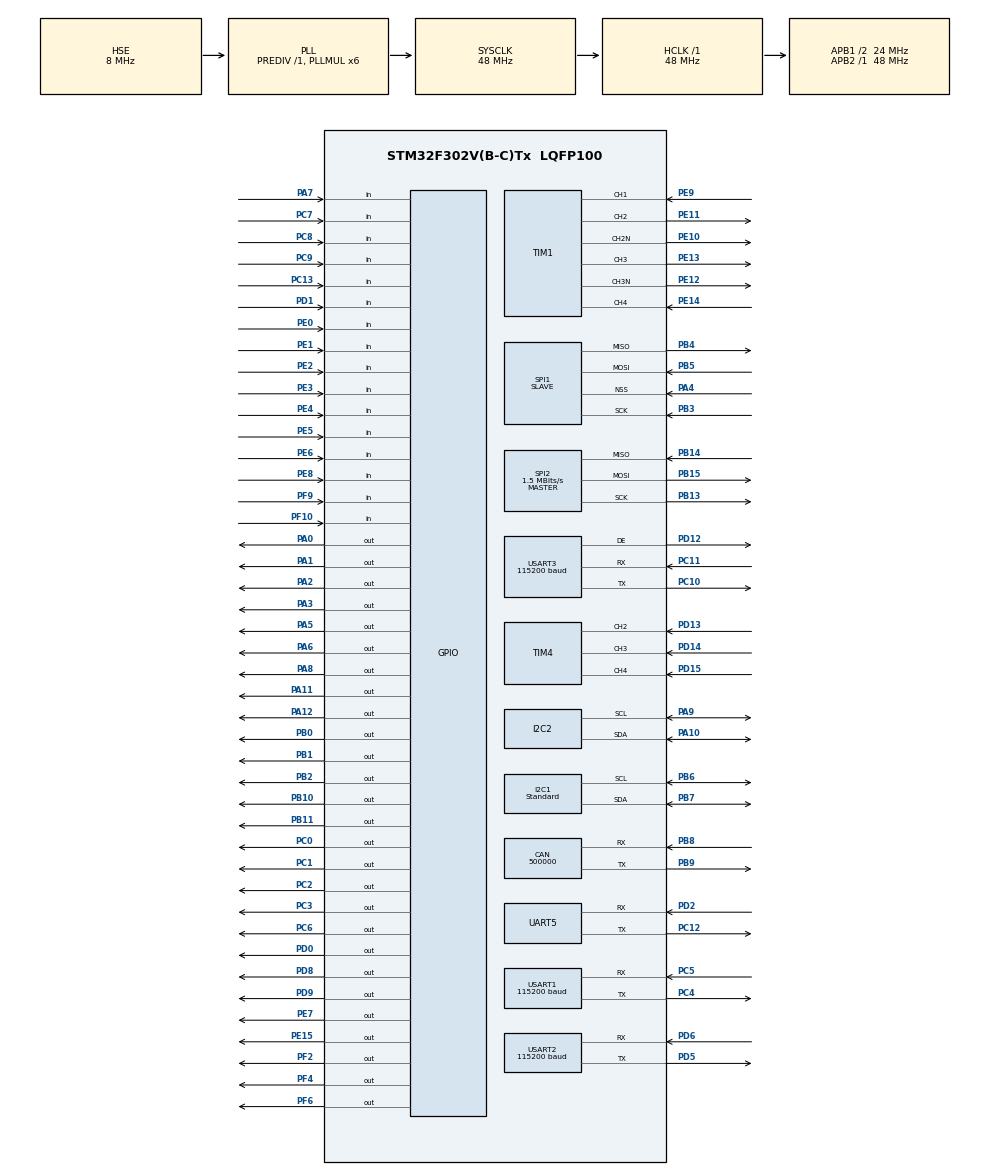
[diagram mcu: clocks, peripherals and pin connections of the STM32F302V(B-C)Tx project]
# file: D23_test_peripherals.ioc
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CAN.CalculateBaudRate=500000
CAN.CalculateTimeBit=2000
CAN.CalculateTimeQuantum=666.6666666666666
I2C1.AddressingMode=I2C_ADDRESSINGMODE_7BIT
I2C1.I2C_Speed_Mode=I2C_Standard
Mcu.Family=STM32F3
Mcu.Name=STM32F302V(B-C)Tx
Mcu.Package=LQFP100
NVIC.PriorityGroup=NVIC_PRIORITYGROUP_4
PA0.Signal=GPIO_Output
PA1.Signal=GPIO_Output
PA10.Mode=I2C
PA10.Signal=I2C2_SDA
PA11.Signal=GPIO_Output
PA12.Signal=GPIO_Output
PA13.Mode=Serial_Wire
PA13.Signal=SYS_JTMS-SWDIO
PA14.Mode=Serial_Wire
PA14.Signal=SYS_JTCK-SWCLK
PA15.Signal=SYS_JTDI
PA2.Signal=GPIO_Output
PA3.Signal=GPIO_Output
PA4.Mode=NSS_Signal_Hard_Input
PA4.Signal=SPI1_NSS
PA5.Signal=GPIO_Output
PA6.Signal=GPIO_Output
PA7.Signal=GPIO_Input
PA8.Signal=GPIO_Output
PA9.Mode=I2C
PA9.Signal=I2C2_SCL
PB0.Signal=GPIO_Output
PB1.Signal=GPIO_Output
PB10.Signal=GPIO_Output
PB11.Signal=GPIO_Output
PB12.Signal=SPI2_NSS
PB13.Mode=Full_Duplex_Master
PB13.Signal=SPI2_SCK
PB14.Mode=Full_Duplex_Master
PB14.Signal=SPI2_MISO
PB15.Mode=Full_Duplex_Master
PB15.Signal=SPI2_MOSI
PB2.Signal=GPIO_Output
PB3.Mode=Full_Duplex_Slave
PB3.Signal=SPI1_SCK
PB4.Mode=Full_Duplex_Slave
PB4.Signal=SPI1_MISO
PB5.Mode=Full_Duplex_Slave
PB5.Signal=SPI1_MOSI
PB6.Mode=I2C
PB6.Signal=I2C1_SCL
PB7.Mode=I2C
PB7.Signal=I2C1_SDA
PB8.Mode=CAN_Activate
PB8.Signal=CAN_RX
PB9.Mode=CAN_Activate
PB9.Signal=CAN_TX
PC0.Signal=GPIO_Output
PC1.Signal=GPIO_Output
PC10.Mode=Asynchronous
PC10.Signal=USART3_TX
PC11.Mode=Asynchronous
PC11.Signal=USART3_RX
PC12.Mode=Asynchronous
PC12.Signal=UART5_TX
PC13.Signal=GPIO_Input
PC14-OSC32_IN.Mode=LSE-External-Oscillator
PC14-OSC32_IN.Signal=RCC_OSC32_IN
PC15-OSC32_OUT.Mode=LSE-External-Oscillator
PC15-OSC32_OUT.Signal=RCC_OSC32_OUT
PC2.Signal=GPIO_Output
PC3.Signal=GPIO_Output
PC4.Mode=Asynchronous
PC4.Signal=USART1_TX
PC5.Mode=Asynchronous
PC5.Signal=USART1_RX
PC6.Signal=GPIO_Output
PC7.Signal=GPIO_Input
PC8.Signal=GPIO_Input
PC9.Signal=GPIO_Input
PD0.Signal=GPIO_Output
PD1.Signal=GPIO_Input
PD10.Signal=USART3_CK
PD11.Signal=USART3_CTS
PD12.Mode=Hardware Flow Control (RS485)
PD12.Signal=USART3_DE
PD13.Signal=S_TIM4_CH2
PD14.Signal=S_TIM4_CH3
PD15.Signal=S_TIM4_CH4
PD2.Mode=Asynchronous
PD2.Signal=UART5_RX
PD3.Signal=USART2_CTS
PD4.Signal=USART2_RTS
PD5.Mode=Asynchronous
PD5.Signal=USART2_TX
PD6.Mode=Asynchronous
PD6.Signal=USART2_RX
PD7.Signal=USART2_CK
PD8.Signal=GPIO_Output
PD9.Signal=GPIO_Output
PE0.Signal=GPIO_Input
PE1.Signal=GPIO_Input
PE10.Mode=Output Compare2 CH2 CH2N
PE10.Signal=TIM1_CH2N
PE11.Signal=S_TIM1_CH2
PE12.Mode=Output Compare3 CH3 CH3N
PE12.Signal=TIM1_CH3N
PE13.Signal=S_TIM1_CH3
PE14.Signal=S_TIM1_CH4
PE15.Signal=GPIO_Output
PE2.Signal=GPIO_Input
PE3.Signal=GPIO_Input
PE4.Signal=GPIO_Input
PE5.Signal=GPIO_Input
PE6.Signal=GPIO_Input
PE7.Signal=GPIO_Output
PE8.Signal=GPIO_Input
PE9.Signal=S_TIM1_CH1
PF0-OSC_IN.Mode=HSE-External-Oscillator
PF0-OSC_IN.Signal=RCC_OSC_IN
PF1-OSC_OUT.Mode=HSE-External-Oscillator
PF1-OSC_OUT.Signal=RCC_OSC_OUT
PF10.Signal=GPIO_Input
PF2.Signal=GPIO_Output
PF4.Signal=GPIO_Output
PF6.Signal=GPIO_Output
PF9.Signal=GPIO_Input
ProjectManager.HeapSize=0x200
ProjectManager.StackSize=0x400
ProjectManager.TargetToolchain=STM32CubeIDE
RCC.AHBFreq_Value=48000000
RCC.APB1CLKDivider=RCC_HCLK_DIV2
RCC.APB1Freq_Value=24000000
RCC.APB1TimFreq_Value=48000000
RCC.APB2Freq_Value=48000000
RCC.APB2TimFreq_Value=48000000
RCC.CortexFreq_Value=48000000
RCC.HCLKFreq_Value=48000000
RCC.HSE_VALUE=8000000
RCC.HSI_VALUE=8000000
RCC.PLLMUL=RCC_PLL_MUL6
RCC.PLLSourceVirtual=RCC_PLLSOURCE_HSE
RCC.SYSCLKFreq_VALUE=48000000
RCC.SYSCLKSourceVirtual=RCC_SYSCLKSOURCE_PLLCLK
RCC.USBFreq_Value=48000000
SH.S_TIM1_CH1.0=TIM1_CH1,Input_Capture1_from_TI1
SH.S_TIM1_CH2.0=TIM1_CH2,Output Compare2 CH2 CH2N
SH.S_TIM1_CH3.0=TIM1_CH3,Output Compare3 CH3 CH3N
SH.S_TIM1_CH4.0=TIM1_CH4,Input_Capture4_from_TI4
SH.S_TIM4_CH2.0=TIM4_CH2,Input_Capture2_from_TI2
SH.S_TIM4_CH3.0=TIM4_CH3,Input_Capture3_from_TI3
SH.S_TIM4_CH4.0=TIM4_CH4,Input_Capture4_from_TI4
SPI1.DataSize=SPI_DATASIZE_8BIT
SPI1.Direction=SPI_DIRECTION_2LINES
SPI1.Mode=SPI_MODE_SLAVE
SPI1.VirtualNSS=VM_NSSHARD
SPI1.VirtualType=VM_SLAVE
SPI2.BaudRatePrescaler=SPI_BAUDRATEPRESCALER_16
SPI2.CalculateBaudRate=1.5 MBits/s
SPI2.DataSize=SPI_DATASIZE_8BIT
SPI2.Direction=SPI_DIRECTION_2LINES
SPI2.Mode=SPI_MODE_MASTER
SPI2.VirtualType=VM_MASTER
TIM1.Channel-Input_Capture1_from_TI1=TIM_CHANNEL_1
TIM1.Channel-Input_Capture4_from_TI4=TIM_CHANNEL_4
TIM1.Channel-Output\ Compare2\ CH2\ CH2N=TIM_CHANNEL_2
TIM1.Channel-Output\ Compare3\ CH3\ CH3N=TIM_CHANNEL_3
TIM4.Channel-Input_Capture2_from_TI2=TIM_CHANNEL_2
TIM4.Channel-Input_Capture3_from_TI3=TIM_CHANNEL_3
TIM4.Channel-Input_Capture4_from_TI4=TIM_CHANNEL_4
USART1.BaudRate=115200
USART1.OneBitSampling=UART_ONE_BIT_SAMPLE_DISABLE
USART1.VirtualMode-Asynchronous=VM_ASYNC
USART2.BaudRate=115200
USART2.VirtualMode-Asynchronous=VM_ASYNC
USART2.VirtualMode-Hardware\ Flow\ Control\ (RS485)=VM_ASYNC
USART3.BaudRate=115200
USART3.VirtualMode-Asynchronous=VM_ASYNC
USART3.VirtualMode-Hardware\ Flow\ Control\ (RS485)=VM_ASYNC
board=custom

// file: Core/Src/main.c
/* USER CODE BEGIN Header */
/**
  ******************************************************************************
  * @file           : main.c
  * @brief          : Main program body
  ******************************************************************************
  * @attention
  *
  * Copyright (c) 2023 STMicroelectronics.
  * All rights reserved.
  *
  * This software is licensed under terms that can be found in the LICENSE file
  * in the root directory of this software component.
  * If no LICENSE file comes with this software, it is provided AS-IS.
  *
  ******************************************************************************
  */
/* USER CODE END Header */
#include "main.h"

/* USER CODE BEGIN Includes */
#include "app_test.h"
#include "app_term_manager.h"
/* USER CODE END Includes */

CAN_HandleTypeDef hcan;

I2C_HandleTypeDef hi2c1;
I2C_HandleTypeDef hi2c2;

SPI_HandleTypeDef hspi1;
SPI_HandleTypeDef hspi2;

TIM_HandleTypeDef htim1;
TIM_HandleTypeDef htim4;

UART_HandleTypeDef huart5;
UART_HandleTypeDef huart1;
UART_HandleTypeDef huart2;
UART_HandleTypeDef huart3;

void SystemClock_Config(void);
static void MX_GPIO_Init(void);
static void MX_CAN_Init(void);
static void MX_I2C1_Init(void);
static void MX_I2C2_Init(void);
static void MX_SPI2_Init(void);
static void MX_TIM1_Init(void);
static void MX_UART5_Init(void);
static void MX_USART1_UART_Init(void);
static void MX_USART2_UART_Init(void);
static void MX_USART3_UART_Init(void);
static void MX_SPI1_Init(void);
static void MX_TIM4_Init(void);

int main(void)
{

  /* MCU Configuration--------------------------------------------------------*/

  /* Reset of all peripherals, Initializes the Flash interface and the Systick. */
  HAL_Init();

  /* Configure the system clock */
  SystemClock_Config();

  /* USER CODE BEGIN SysInit */
  HAL_InitTick(TICK_INT_PRIORITY);
  /* USER CODE END SysInit */

  /* Initialize all configured peripherals */
  MX_GPIO_Init();
  MX_CAN_Init();
  MX_I2C1_Init();
  MX_I2C2_Init();
  MX_SPI2_Init();
  MX_TIM1_Init();
  MX_UART5_Init();
  MX_USART1_UART_Init();
  MX_USART2_UART_Init();
  MX_USART3_UART_Init();
  MX_SPI1_Init();
  MX_TIM4_Init();
  /* USER CODE BEGIN 2 */
  __HAL_TIM_SET_COMPARE(&htim4, TIM_CHANNEL_2, htim4.Init.Period / 2);
  __HAL_TIM_SET_COMPARE(&htim4, TIM_CHANNEL_3, htim4.Init.Period / 2);
  __HAL_TIM_SET_COMPARE(&htim4, TIM_CHANNEL_4, htim4.Init.Period / 2);
  __HAL_TIM_SET_COMPARE(&htim1, TIM_CHANNEL_1, htim1.Init.Period / 2);
  __HAL_TIM_SET_COMPARE(&htim1, TIM_CHANNEL_2, htim1.Init.Period / 2);
  __HAL_TIM_SET_COMPARE(&htim1, TIM_CHANNEL_3, htim1.Init.Period / 2);
  __HAL_TIM_SET_COMPARE(&htim1, TIM_CHANNEL_4, htim1.Init.Period / 2);

  HAL_GPIO_WritePin(GPIOE, GPIO_PIN_7 | GPIO_PIN_15, GPIO_PIN_SET);
  /* USER CODE END 2 */

  /* Infinite loop */
  while (1)
  {

    /* USER CODE BEGIN 3 */
	  app_term_manager_sm();

	  // review test manager
	  app_test_manager_sm();

  }
  /* USER CODE END 3 */
}

void SystemClock_Config(void)
{
  RCC_OscInitTypeDef RCC_OscInitStruct = {0};
  RCC_ClkInitTypeDef RCC_ClkInitStruct = {0};
  RCC_PeriphCLKInitTypeDef PeriphClkInit = {0};

  /** Initializes the RCC Oscillators according to the specified parameters
  * in the RCC_OscInitTypeDef structure.
  */
  RCC_OscInitStruct.OscillatorType = RCC_OSCILLATORTYPE_HSI|RCC_OSCILLATORTYPE_HSE;
  RCC_OscInitStruct.HSEState = RCC_HSE_ON;
  RCC_OscInitStruct.HSEPredivValue = RCC_HSE_PREDIV_DIV1;
  RCC_OscInitStruct.HSIState = RCC_HSI_ON;
  RCC_OscInitStruct.HSICalibrationValue = RCC_HSICALIBRATION_DEFAULT;
  RCC_OscInitStruct.PLL.PLLState = RCC_PLL_ON;
  RCC_OscInitStruct.PLL.PLLSource = RCC_PLLSOURCE_HSE;
  RCC_OscInitStruct.PLL.PLLMUL = RCC_PLL_MUL6;
  if (HAL_RCC_OscConfig(&RCC_OscInitStruct) != HAL_OK)
  {
    Error_Handler();
  }

  /** Initializes the CPU, AHB and APB buses clocks
  */
  RCC_ClkInitStruct.ClockType = RCC_CLOCKTYPE_HCLK|RCC_CLOCKTYPE_SYSCLK
                              |RCC_CLOCKTYPE_PCLK1|RCC_CLOCKTYPE_PCLK2;
  RCC_ClkInitStruct.SYSCLKSource = RCC_SYSCLKSOURCE_PLLCLK;
  RCC_ClkInitStruct.AHBCLKDivider = RCC_SYSCLK_DIV1;
  RCC_ClkInitStruct.APB1CLKDivider = RCC_HCLK_DIV2;
  RCC_ClkInitStruct.APB2CLKDivider = RCC_HCLK_DIV1;

  if (HAL_RCC_ClockConfig(&RCC_ClkInitStruct, FLASH_LATENCY_1) != HAL_OK)
  {
    Error_Handler();
  }
  PeriphClkInit.PeriphClockSelection = RCC_PERIPHCLK_USART1|RCC_PERIPHCLK_USART2
                              |RCC_PERIPHCLK_USART3|RCC_PERIPHCLK_UART5
                              |RCC_PERIPHCLK_I2C1|RCC_PERIPHCLK_I2C2
                              |RCC_PERIPHCLK_TIM1;
  PeriphClkInit.Usart1ClockSelection = RCC_USART1CLKSOURCE_PCLK2;
  PeriphClkInit.Usart2ClockSelection = RCC_USART2CLKSOURCE_PCLK1;
  PeriphClkInit.Usart3ClockSelection = RCC_USART3CLKSOURCE_PCLK1;
  PeriphClkInit.Uart5ClockSelection = RCC_UART5CLKSOURCE_PCLK1;
  PeriphClkInit.I2c1ClockSelection = RCC_I2C1CLKSOURCE_HSI;
  PeriphClkInit.I2c2ClockSelection = RCC_I2C2CLKSOURCE_HSI;
  PeriphClkInit.Tim1ClockSelection = RCC_TIM1CLK_HCLK;
  if (HAL_RCCEx_PeriphCLKConfig(&PeriphClkInit) != HAL_OK)
  {
    Error_Handler();
  }
}

static void MX_CAN_Init(void)
{

  hcan.Instance = CAN;
  hcan.Init.Prescaler = 16;
  hcan.Init.Mode = CAN_MODE_NORMAL;
  hcan.Init.SyncJumpWidth = CAN_SJW_1TQ;
  hcan.Init.TimeSeg1 = CAN_BS1_1TQ;
  hcan.Init.TimeSeg2 = CAN_BS2_1TQ;
  hcan.Init.TimeTriggeredMode = DISABLE;
  hcan.Init.AutoBusOff = DISABLE;
  hcan.Init.AutoWakeUp = DISABLE;
  hcan.Init.AutoRetransmission = DISABLE;
  hcan.Init.ReceiveFifoLocked = DISABLE;
  hcan.Init.TransmitFifoPriority = DISABLE;
  if (HAL_CAN_Init(&hcan) != HAL_OK)
  {
    Error_Handler();
  }

}

static void MX_I2C1_Init(void)
{

  hi2c1.Instance = I2C1;
  hi2c1.Init.Timing = 0x2000090E;
  hi2c1.Init.OwnAddress1 = 0;
  hi2c1.Init.AddressingMode = I2C_ADDRESSINGMODE_7BIT;
  hi2c1.Init.DualAddressMode = I2C_DUALADDRESS_DISABLE;
  hi2c1.Init.OwnAddress2 = 0;
  hi2c1.Init.OwnAddress2Masks = I2C_OA2_NOMASK;
  hi2c1.Init.GeneralCallMode = I2C_GENERALCALL_DISABLE;
  hi2c1.Init.NoStretchMode = I2C_NOSTRETCH_DISABLE;
  if (HAL_I2C_Init(&hi2c1) != HAL_OK)
  {
    Error_Handler();
  }

  /** Configure Analogue filter
  */
  if (HAL_I2CEx_ConfigAnalogFilter(&hi2c1, I2C_ANALOGFILTER_ENABLE) != HAL_OK)
  {
    Error_Handler();
  }

  /** Configure Digital filter
  */
  if (HAL_I2CEx_ConfigDigitalFilter(&hi2c1, 0) != HAL_OK)
  {
    Error_Handler();
  }

}

static void MX_I2C2_Init(void)
{

  hi2c2.Instance = I2C2;
  hi2c2.Init.Timing = 0x2000090E;
  hi2c2.Init.OwnAddress1 = 0;
  hi2c2.Init.AddressingMode = I2C_ADDRESSINGMODE_7BIT;
  hi2c2.Init.DualAddressMode = I2C_DUALADDRESS_DISABLE;
  hi2c2.Init.OwnAddress2 = 0;
  hi2c2.Init.OwnAddress2Masks = I2C_OA2_NOMASK;
  hi2c2.Init.GeneralCallMode = I2C_GENERALCALL_DISABLE;
  hi2c2.Init.NoStretchMode = I2C_NOSTRETCH_DISABLE;
  if (HAL_I2C_Init(&hi2c2) != HAL_OK)
  {
    Error_Handler();
  }

  /** Configure Analogue filter
  */
  if (HAL_I2CEx_ConfigAnalogFilter(&hi2c2, I2C_ANALOGFILTER_ENABLE) != HAL_OK)
  {
    Error_Handler();
  }

  /** Configure Digital filter
  */
  if (HAL_I2CEx_ConfigDigitalFilter(&hi2c2, 0) != HAL_OK)
  {
    Error_Handler();
  }

}

static void MX_SPI1_Init(void)
{

  /* SPI1 parameter configuration*/
  hspi1.Instance = SPI1;
  hspi1.Init.Mode = SPI_MODE_SLAVE;
  hspi1.Init.Direction = SPI_DIRECTION_2LINES;
  hspi1.Init.DataSize = SPI_DATASIZE_8BIT;
  hspi1.Init.CLKPolarity = SPI_POLARITY_LOW;
  hspi1.Init.CLKPhase = SPI_PHASE_1EDGE;
  hspi1.Init.NSS = SPI_NSS_HARD_INPUT;
  hspi1.Init.FirstBit = SPI_FIRSTBIT_MSB;
  hspi1.Init.TIMode = SPI_TIMODE_DISABLE;
  hspi1.Init.CRCCalculation = SPI_CRCCALCULATION_DISABLE;
  hspi1.Init.CRCPolynomial = 7;
  hspi1.Init.CRCLength = SPI_CRC_LENGTH_DATASIZE;
  hspi1.Init.NSSPMode = SPI_NSS_PULSE_DISABLE;
  if (HAL_SPI_Init(&hspi1) != HAL_OK)
  {
    Error_Handler();
  }

}

static void MX_SPI2_Init(void)
{

  /* SPI2 parameter configuration*/
  hspi2.Instance = SPI2;
  hspi2.Init.Mode = SPI_MODE_MASTER;
  hspi2.Init.Direction = SPI_DIRECTION_2LINES;
  hspi2.Init.DataSize = SPI_DATASIZE_8BIT;
  hspi2.Init.CLKPolarity = SPI_POLARITY_LOW;
  hspi2.Init.CLKPhase = SPI_PHASE_1EDGE;
  hspi2.Init.NSS = SPI_NSS_SOFT;
  hspi2.Init.BaudRatePrescaler = SPI_BAUDRATEPRESCALER_16;
  hspi2.Init.FirstBit = SPI_FIRSTBIT_MSB;
  hspi2.Init.TIMode = SPI_TIMODE_DISABLE;
  hspi2.Init.CRCCalculation = SPI_CRCCALCULATION_DISABLE;
  hspi2.Init.CRCPolynomial = 7;
  hspi2.Init.CRCLength = SPI_CRC_LENGTH_DATASIZE;
  hspi2.Init.NSSPMode = SPI_NSS_PULSE_ENABLE;
  if (HAL_SPI_Init(&hspi2) != HAL_OK)
  {
    Error_Handler();
  }

}

static void MX_TIM1_Init(void)
{

  TIM_MasterConfigTypeDef sMasterConfig = {0};
  TIM_IC_InitTypeDef sConfigIC = {0};
  TIM_OC_InitTypeDef sConfigOC = {0};
  TIM_BreakDeadTimeConfigTypeDef sBreakDeadTimeConfig = {0};

  htim1.Instance = TIM1;
  htim1.Init.Prescaler = 0;
  htim1.Init.CounterMode = TIM_COUNTERMODE_UP;
  htim1.Init.Period = 65535;
  htim1.Init.ClockDivision = TIM_CLOCKDIVISION_DIV1;
  htim1.Init.RepetitionCounter = 0;
  htim1.Init.AutoReloadPreload = TIM_AUTORELOAD_PRELOAD_DISABLE;
  if (HAL_TIM_IC_Init(&htim1) != HAL_OK)
  {
    Error_Handler();
  }
  if (HAL_TIM_OC_Init(&htim1) != HAL_OK)
  {
    Error_Handler();
  }
  sMasterConfig.MasterOutputTrigger = TIM_TRGO_RESET;
  sMasterConfig.MasterOutputTrigger2 = TIM_TRGO2_RESET;
  sMasterConfig.MasterSlaveMode = TIM_MASTERSLAVEMODE_DISABLE;
  if (HAL_TIMEx_MasterConfigSynchronization(&htim1, &sMasterConfig) != HAL_OK)
  {
    Error_Handler();
  }
  sConfigIC.ICPolarity = TIM_INPUTCHANNELPOLARITY_RISING;
  sConfigIC.ICSelection = TIM_ICSELECTION_DIRECTTI;
  sConfigIC.ICPrescaler = TIM_ICPSC_DIV1;
  sConfigIC.ICFilter = 0;
  if (HAL_TIM_IC_ConfigChannel(&htim1, &sConfigIC, TIM_CHANNEL_1) != HAL_OK)
  {
    Error_Handler();
  }
  sConfigOC.OCMode = TIM_OCMODE_TIMING;
  sConfigOC.Pulse = 0;
  sConfigOC.OCPolarity = TIM_OCPOLARITY_HIGH;
  sConfigOC.OCNPolarity = TIM_OCNPOLARITY_HIGH;
  sConfigOC.OCFastMode = TIM_OCFAST_DISABLE;
  sConfigOC.OCIdleState = TIM_OCIDLESTATE_RESET;
  sConfigOC.OCNIdleState = TIM_OCNIDLESTATE_RESET;
  if (HAL_TIM_OC_ConfigChannel(&htim1, &sConfigOC, TIM_CHANNEL_2) != HAL_OK)
  {
    Error_Handler();
  }
  if (HAL_TIM_OC_ConfigChannel(&htim1, &sConfigOC, TIM_CHANNEL_3) != HAL_OK)
  {
    Error_Handler();
  }
  if (HAL_TIM_IC_ConfigChannel(&htim1, &sConfigIC, TIM_CHANNEL_4) != HAL_OK)
  {
    Error_Handler();
  }
  sBreakDeadTimeConfig.OffStateRunMode = TIM_OSSR_DISABLE;
  sBreakDeadTimeConfig.OffStateIDLEMode = TIM_OSSI_DISABLE;
  sBreakDeadTimeConfig.LockLevel = TIM_LOCKLEVEL_OFF;
  sBreakDeadTimeConfig.DeadTime = 0;
  sBreakDeadTimeConfig.BreakState = TIM_BREAK_DISABLE;
  sBreakDeadTimeConfig.BreakPolarity = TIM_BREAKPOLARITY_HIGH;
  sBreakDeadTimeConfig.BreakFilter = 0;
  sBreakDeadTimeConfig.Break2State = TIM_BREAK2_DISABLE;
  sBreakDeadTimeConfig.Break2Polarity = TIM_BREAK2POLARITY_HIGH;
  sBreakDeadTimeConfig.Break2Filter = 0;
  sBreakDeadTimeConfig.AutomaticOutput = TIM_AUTOMATICOUTPUT_DISABLE;
  if (HAL_TIMEx_ConfigBreakDeadTime(&htim1, &sBreakDeadTimeConfig) != HAL_OK)
  {
    Error_Handler();
  }
  HAL_TIM_MspPostInit(&htim1);

}

static void MX_TIM4_Init(void)
{

  TIM_MasterConfigTypeDef sMasterConfig = {0};
  TIM_IC_InitTypeDef sConfigIC = {0};

  htim4.Instance = TIM4;
  htim4.Init.Prescaler = 0;
  htim4.Init.CounterMode = TIM_COUNTERMODE_UP;
  htim4.Init.Period = 65535;
  htim4.Init.ClockDivision = TIM_CLOCKDIVISION_DIV1;
  htim4.Init.AutoReloadPreload = TIM_AUTORELOAD_PRELOAD_DISABLE;
  if (HAL_TIM_IC_Init(&htim4) != HAL_OK)
  {
    Error_Handler();
  }
  sMasterConfig.MasterOutputTrigger = TIM_TRGO_RESET;
  sMasterConfig.MasterSlaveMode = TIM_MASTERSLAVEMODE_DISABLE;
  if (HAL_TIMEx_MasterConfigSynchronization(&htim4, &sMasterConfig) != HAL_OK)
  {
    Error_Handler();
  }
  sConfigIC.ICPolarity = TIM_INPUTCHANNELPOLARITY_RISING;
  sConfigIC.ICSelection = TIM_ICSELECTION_DIRECTTI;
  sConfigIC.ICPrescaler = TIM_ICPSC_DIV1;
  sConfigIC.ICFilter = 0;
  if (HAL_TIM_IC_ConfigChannel(&htim4, &sConfigIC, TIM_CHANNEL_2) != HAL_OK)
  {
    Error_Handler();
  }
  if (HAL_TIM_IC_ConfigChannel(&htim4, &sConfigIC, TIM_CHANNEL_3) != HAL_OK)
  {
    Error_Handler();
  }
  if (HAL_TIM_IC_ConfigChannel(&htim4, &sConfigIC, TIM_CHANNEL_4) != HAL_OK)
  {
    Error_Handler();
  }

}

static void MX_UART5_Init(void)
{

  huart5.Instance = UART5;
  huart5.Init.BaudRate = 115200;
  huart5.Init.WordLength = UART_WORDLENGTH_8B;
  huart5.Init.StopBits = UART_STOPBITS_1;
  huart5.Init.Parity = UART_PARITY_NONE;
  huart5.Init.Mode = UART_MODE_TX_RX;
  huart5.Init.HwFlowCtl = UART_HWCONTROL_NONE;
  huart5.Init.OverSampling = UART_OVERSAMPLING_16;
  huart5.Init.OneBitSampling = UART_ONE_BIT_SAMPLE_DISABLE;
  huart5.AdvancedInit.AdvFeatureInit = UART_ADVFEATURE_NO_INIT;
  if (HAL_UART_Init(&huart5) != HAL_OK)
  {
    Error_Handler();
  }

}

static void MX_USART1_UART_Init(void)
{

  huart1.Instance = USART1;
  huart1.Init.BaudRate = 115200;
  huart1.Init.WordLength = UART_WORDLENGTH_8B;
  huart1.Init.StopBits = UART_STOPBITS_1;
  huart1.Init.Parity = UART_PARITY_NONE;
  huart1.Init.Mode = UART_MODE_TX_RX;
  huart1.Init.HwFlowCtl = UART_HWCONTROL_NONE;
  huart1.Init.OverSampling = UART_OVERSAMPLING_16;
  huart1.Init.OneBitSampling = UART_ONE_BIT_SAMPLE_DISABLE;
  huart1.AdvancedInit.AdvFeatureInit = UART_ADVFEATURE_NO_INIT;
  if (HAL_UART_Init(&huart1) != HAL_OK)
  {
    Error_Handler();
  }

}

static void MX_USART2_UART_Init(void)
{

  huart2.Instance = USART2;
  huart2.Init.BaudRate = 115200;
  huart2.Init.WordLength = UART_WORDLENGTH_8B;
  huart2.Init.StopBits = UART_STOPBITS_1;
  huart2.Init.Parity = UART_PARITY_NONE;
  huart2.Init.Mode = UART_MODE_TX_RX;
  huart2.Init.HwFlowCtl = UART_HWCONTROL_NONE;
  huart2.Init.OverSampling = UART_OVERSAMPLING_16;
  huart2.Init.OneBitSampling = UART_ONE_BIT_SAMPLE_DISABLE;
  huart2.AdvancedInit.AdvFeatureInit = UART_ADVFEATURE_NO_INIT;
  if (HAL_UART_Init(&huart2) != HAL_OK)
  {
    Error_Handler();
  }

}

static void MX_USART3_UART_Init(void)
{

  huart3.Instance = USART3;
  huart3.Init.BaudRate = 115200;
  huart3.Init.WordLength = UART_WORDLENGTH_8B;
  huart3.Init.StopBits = UART_STOPBITS_1;
  huart3.Init.Parity = UART_PARITY_NONE;
  huart3.Init.Mode = UART_MODE_TX_RX;
  huart3.Init.HwFlowCtl = UART_HWCONTROL_NONE;
  huart3.Init.OverSampling = UART_OVERSAMPLING_16;
  huart3.Init.OneBitSampling = UART_ONE_BIT_SAMPLE_DISABLE;
  huart3.AdvancedInit.AdvFeatureInit = UART_ADVFEATURE_NO_INIT;
  if (HAL_RS485Ex_Init(&huart3, UART_DE_POLARITY_HIGH, 0, 0) != HAL_OK)
  {
    Error_Handler();
  }

}

static void MX_GPIO_Init(void)
{
  GPIO_InitTypeDef GPIO_InitStruct = {0};

  /* GPIO Ports Clock Enable */
  __HAL_RCC_GPIOE_CLK_ENABLE();
  __HAL_RCC_GPIOC_CLK_ENABLE();
  __HAL_RCC_GPIOF_CLK_ENABLE();
  __HAL_RCC_GPIOA_CLK_ENABLE();
  __HAL_RCC_GPIOB_CLK_ENABLE();
  __HAL_RCC_GPIOD_CLK_ENABLE();

  /*Configure GPIO pin Output Level */
  HAL_GPIO_WritePin(GPIOC, GPIO_PIN_0|GPIO_PIN_1|GPIO_PIN_2|GPIO_PIN_3
                          |GPIO_PIN_6, GPIO_PIN_RESET);

  /*Configure GPIO pin Output Level */
  HAL_GPIO_WritePin(GPIOF, GPIO_PIN_2|GPIO_PIN_4|GPIO_PIN_6, GPIO_PIN_RESET);

  /*Configure GPIO pin Output Level */
  HAL_GPIO_WritePin(GPIOA, GPIO_PIN_0|GPIO_PIN_1|GPIO_PIN_2|GPIO_PIN_3
                          |GPIO_PIN_5|GPIO_PIN_6|GPIO_PIN_8|GPIO_PIN_11
                          |GPIO_PIN_12, GPIO_PIN_RESET);

  /*Configure GPIO pin Output Level */
  HAL_GPIO_WritePin(GPIOB, GPIO_PIN_0|GPIO_PIN_1|GPIO_PIN_2|GPIO_PIN_10
                          |GPIO_PIN_11, GPIO_PIN_RESET);

  /*Configure GPIO pin Output Level */
  HAL_GPIO_WritePin(GPIOE, GPIO_PIN_7|GPIO_PIN_15, GPIO_PIN_RESET);

  /*Configure GPIO pin Output Level */
  HAL_GPIO_WritePin(GPIOD, GPIO_PIN_8|GPIO_PIN_9|GPIO_PIN_0, GPIO_PIN_RESET);

  /*Configure GPIO pins : PE2 PE3 PE4 PE5
                           PE6 PE8 PE0 PE1 */
  GPIO_InitStruct.Pin = GPIO_PIN_2|GPIO_PIN_3|GPIO_PIN_4|GPIO_PIN_5
                          |GPIO_PIN_6|GPIO_PIN_8|GPIO_PIN_0|GPIO_PIN_1;
  GPIO_InitStruct.Mode = GPIO_MODE_INPUT;
  GPIO_InitStruct.Pull = GPIO_NOPULL;
  HAL_GPIO_Init(GPIOE, &GPIO_InitStruct);

  /*Configure GPIO pins : PC13 PC7 PC8 PC9 */
  GPIO_InitStruct.Pin = GPIO_PIN_13|GPIO_PIN_7|GPIO_PIN_8|GPIO_PIN_9;
  GPIO_InitStruct.Mode = GPIO_MODE_INPUT;
  GPIO_InitStruct.Pull = GPIO_NOPULL;
  HAL_GPIO_Init(GPIOC, &GPIO_InitStruct);

  /*Configure GPIO pins : PF9 PF10 */
  GPIO_InitStruct.Pin = GPIO_PIN_9|GPIO_PIN_10;
  GPIO_InitStruct.Mode = GPIO_MODE_INPUT;
  GPIO_InitStruct.Pull = GPIO_NOPULL;
  HAL_GPIO_Init(GPIOF, &GPIO_InitStruct);

  /*Configure GPIO pins : PC0 PC1 PC2 PC3
                           PC6 */
  GPIO_InitStruct.Pin = GPIO_PIN_0|GPIO_PIN_1|GPIO_PIN_2|GPIO_PIN_3
                          |GPIO_PIN_6;
  GPIO_InitStruct.Mode = GPIO_MODE_OUTPUT_PP;
  GPIO_InitStruct.Pull = GPIO_NOPULL;
  GPIO_InitStruct.Speed = GPIO_SPEED_FREQ_LOW;
  HAL_GPIO_Init(GPIOC, &GPIO_InitStruct);

  /*Configure GPIO pins : PF2 PF4 PF6 */
  GPIO_InitStruct.Pin = GPIO_PIN_2|GPIO_PIN_4|GPIO_PIN_6;
  GPIO_InitStruct.Mode = GPIO_MODE_OUTPUT_PP;
  GPIO_InitStruct.Pull = GPIO_NOPULL;
  GPIO_InitStruct.Speed = GPIO_SPEED_FREQ_LOW;
  HAL_GPIO_Init(GPIOF, &GPIO_InitStruct);

  /*Configure GPIO pins : PA0 PA1 PA2 PA3
                           PA5 PA6 PA8 PA11
                           PA12 */
  GPIO_InitStruct.Pin = GPIO_PIN_0|GPIO_PIN_1|GPIO_PIN_2|GPIO_PIN_3
                          |GPIO_PIN_5|GPIO_PIN_6|GPIO_PIN_8|GPIO_PIN_11
                          |GPIO_PIN_12;
  GPIO_InitStruct.Mode = GPIO_MODE_OUTPUT_PP;
  GPIO_InitStruct.Pull = GPIO_NOPULL;
  GPIO_InitStruct.Speed = GPIO_SPEED_FREQ_LOW;
  HAL_GPIO_Init(GPIOA, &GPIO_InitStruct);

  /*Configure GPIO pin : PA7 */
  GPIO_InitStruct.Pin = GPIO_PIN_7;
  GPIO_InitStruct.Mode = GPIO_MODE_INPUT;
  GPIO_InitStruct.Pull = GPIO_NOPULL;
  HAL_GPIO_Init(GPIOA, &GPIO_InitStruct);

  /*Configure GPIO pins : PB0 PB1 PB2 PB10
                           PB11 */
  GPIO_InitStruct.Pin = GPIO_PIN_0|GPIO_PIN_1|GPIO_PIN_2|GPIO_PIN_10
                          |GPIO_PIN_11;
  GPIO_InitStruct.Mode = GPIO_MODE_OUTPUT_PP;
  GPIO_InitStruct.Pull = GPIO_NOPULL;
  GPIO_InitStruct.Speed = GPIO_SPEED_FREQ_LOW;
  HAL_GPIO_Init(GPIOB, &GPIO_InitStruct);

  /*Configure GPIO pins : PE7 PE15 */
  GPIO_InitStruct.Pin = GPIO_PIN_7|GPIO_PIN_15;
  GPIO_InitStruct.Mode = GPIO_MODE_OUTPUT_PP;
  GPIO_InitStruct.Pull = GPIO_NOPULL;
  GPIO_InitStruct.Speed = GPIO_SPEED_FREQ_LOW;
  HAL_GPIO_Init(GPIOE, &GPIO_InitStruct);

  /*Configure GPIO pins : PD8 PD9 PD0 */
  GPIO_InitStruct.Pin = GPIO_PIN_8|GPIO_PIN_9|GPIO_PIN_0;
  GPIO_InitStruct.Mode = GPIO_MODE_OUTPUT_PP;
  GPIO_InitStruct.Pull = GPIO_NOPULL;
  GPIO_InitStruct.Speed = GPIO_SPEED_FREQ_LOW;
  HAL_GPIO_Init(GPIOD, &GPIO_InitStruct);

  /*Configure GPIO pin : PD1 */
  GPIO_InitStruct.Pin = GPIO_PIN_1;
  GPIO_InitStruct.Mode = GPIO_MODE_INPUT;
  GPIO_InitStruct.Pull = GPIO_NOPULL;
  HAL_GPIO_Init(GPIOD, &GPIO_InitStruct);

}

void Error_Handler(void)
{
  __disable_irq();
  while (1)
  {
  }
}
